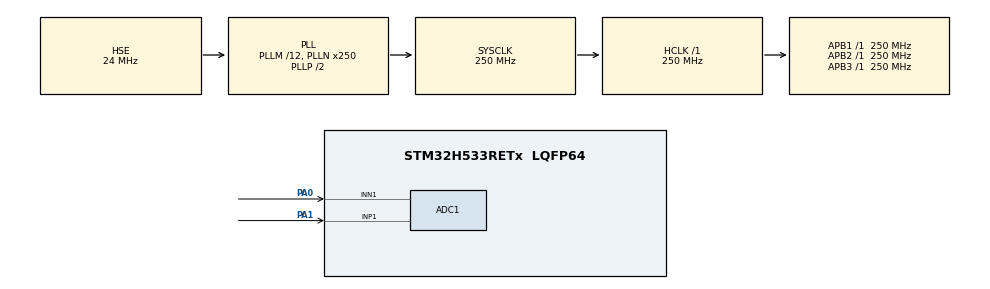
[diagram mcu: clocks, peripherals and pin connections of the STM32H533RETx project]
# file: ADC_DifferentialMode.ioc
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ADC1.Channel-0\#ChannelRegularConversion=ADC_CHANNEL_1
ADC1.ClockPrescaler=ADC_CLOCK_ASYNC_DIV1
ADC1.ContinuousConvMode=ENABLE
ADC1.MonitoredBy-0\#ChannelRegularConversion=__NULL
ADC1.NbrOfConversionFlag=1
ADC1.OffsetNumber-0\#ChannelRegularConversion=ADC_OFFSET_NONE
ADC1.Overrun=ADC_OVR_DATA_OVERWRITTEN
ADC1.Rank-0\#ChannelRegularConversion=1
ADC1.SamplingTime-0\#ChannelRegularConversion=ADC_SAMPLETIME_2CYCLES_5
ADC1.SingleDiff-0\#ChannelRegularConversion=ADC_DIFFERENTIAL_ENDED
ADC1.master=1
BOOTPATH.BootPathName=LEGACY
BOOTPATH.UserSelectedBootPath=LEGACY
CORTEX_M33_NS.userName=CORTEX_M33
Mcu.Family=STM32H5
Mcu.Name=STM32H533RETx
Mcu.Package=LQFP64
NVIC.PriorityGroup=NVIC_PRIORITYGROUP_4
PA0.Signal=ADCx_INN1
PA1.Signal=ADCx_INP1
PH0-OSC_IN(PH0).Mode=HSE-External-Oscillator
PH0-OSC_IN(PH0).Signal=RCC_OSC_IN
PH1-OSC_OUT(PH1).Mode=HSE-External-Oscillator
PH1-OSC_OUT(PH1).Signal=RCC_OSC_OUT
ProjectManager.HeapSize=0x200
ProjectManager.StackSize=0x400
ProjectManager.TargetToolchain=EWARM V9.20
RCC.ADCCLockSelection=RCC_ADCDACCLKSOURCE_HSI
RCC.ADCFreq_Value=64000000
RCC.AHBFreq_Value=250000000
RCC.APB1Freq_Value=250000000
RCC.APB1TimFreq_Value=250000000
RCC.APB2Freq_Value=250000000
RCC.APB2TimFreq_Value=250000000
RCC.APB3Freq_Value=250000000
RCC.CSI_VALUE=4000000
RCC.CortexFreq_Value=250000000
RCC.EPOD_VALUE=24000000
RCC.HCLKFreq_Value=250000000
RCC.HSE_VALUE=24000000
RCC.HSI48_VALUE=48000000
RCC.HSIDiv=RCC_HSI_DIV1
RCC.HSI_VALUE=64000000
RCC.LSE_VALUE=32768
RCC.LSIRC_VALUE=32000
RCC.PLL2FRACN=0
RCC.PLL3FRACN=0
RCC.PLLFRACN=0
RCC.PLLM=12
RCC.PLLN=250
RCC.PLLSourceVirtual=RCC_PLL1_SOURCE_HSE
RCC.SYSCLKFreq_VALUE=250000000
RCC.SYSCLKSource=RCC_SYSCLKSOURCE_PLLCLK
RCC.USBFreq_Value=48000000
RCC.VCOOutputFreq_Value=500000000
SH.ADCx_INN1.0=ADC1_INN1,IN1-Differential
SH.ADCx_INP1.0=ADC1_INP1,IN1-Differential
VP_BOOTPATH_VS_BOOTPATH.Mode=BP_Activate
VP_CORTEX_M33_NS_VS_Hclk.Mode=Hclk_Mode
VP_ICACHE_VS_ICACHE.Mode=DefaultMode
VP_MEMORYMAP_VS_MEMORYMAP.Mode=CurAppReg
VP_PWR_VS_DBSignals.Mode=DisableDeadBatterySignals
VP_PWR_VS_LPOM.Mode=PowerOptimisation
VP_PWR_VS_SECSignals.Mode=Security/Privilege
board=custom

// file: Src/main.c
/* USER CODE BEGIN Header */
/**
  ******************************************************************************
  * @file           : main.c
  * @brief          : Main program body
  ******************************************************************************
  * @attention
  *
  * Copyright (c) 2023 STMicroelectronics.
  * All rights reserved.
  *
  * This software is licensed under terms that can be found in the LICENSE file
  * in the root directory of this software component.
  * If no LICENSE file comes with this software, it is provided AS-IS.
  *
  ******************************************************************************
  */
/* USER CODE END Header */
#include "main.h"

ADC_HandleTypeDef hadc1;

/* USER CODE BEGIN PV */
/* Converted value declaration */
uint32_t                 uhADCxConvertedData;
/* Input voltage declaration */
int32_t                  uhADCxConvertedData_Voltage_mVolt;
/* USER CODE END PV */

void SystemClock_Config(void);
static void MX_GPIO_Init(void);
static void MX_ADC1_Init(void);
static void MX_ICACHE_Init(void);

int main(void)
{

  /* USER CODE BEGIN 1 */
  /* STM32H5xx HAL library initialization:
       - Systick timer is configured by default as source of time base, but user
             can eventually implement his proper time base source (a general purpose
             timer for example or other time source), keeping in mind that Time base
             duration should be kept 1ms since PPP_TIMEOUT_VALUEs are defined and
             handled in milliseconds basis.
       - Set NVIC Group Priority to 4
       - Low Level Initialization
     */
  /* USER CODE END 1 */

  /* MCU Configuration--------------------------------------------------------*/

  /* Reset of all peripherals, Initializes the Flash interface and the Systick. */
  HAL_Init();

  /* Configure the system clock */
  SystemClock_Config();

  /* Initialize all configured peripherals */
  MX_GPIO_Init();
  MX_ADC1_Init();
  MX_ICACHE_Init();

  /* Infinite loop */
  /* USER CODE BEGIN WHILE */
  while (1)
  {
    if (HAL_ADC_PollForConversion(&hadc1, 10) != HAL_OK)
    {
      Error_Handler();
    }

    /* Read the converted value */
    uhADCxConvertedData = HAL_ADC_GetValue(&hadc1);

    /* Computation of ADC conversions raw data to physical values             */
    /* using helper macro.                                                    */
    uhADCxConvertedData_Voltage_mVolt = __HAL_ADC_CALC_DIFF_DATA_TO_VOLTAGE(VDDA_APPLI, uhADCxConvertedData, ADC_RESOLUTION_12B);
    /* USER CODE END WHILE */

  }
}

void SystemClock_Config(void)
{
  RCC_OscInitTypeDef RCC_OscInitStruct = {0};
  RCC_ClkInitTypeDef RCC_ClkInitStruct = {0};

  /** Configure the main internal regulator output voltage
  */
  __HAL_PWR_VOLTAGESCALING_CONFIG(PWR_REGULATOR_VOLTAGE_SCALE0);

  while(!__HAL_PWR_GET_FLAG(PWR_FLAG_VOSRDY)) {}

  /** Initializes the RCC Oscillators according to the specified parameters
  * in the RCC_OscInitTypeDef structure.
  */
  RCC_OscInitStruct.OscillatorType = RCC_OSCILLATORTYPE_HSI|RCC_OSCILLATORTYPE_HSE;
  RCC_OscInitStruct.HSEState = RCC_HSE_ON;
  RCC_OscInitStruct.HSIState = RCC_HSI_ON;
  RCC_OscInitStruct.HSIDiv = RCC_HSI_DIV1;
  RCC_OscInitStruct.HSICalibrationValue = RCC_HSICALIBRATION_DEFAULT;
  RCC_OscInitStruct.PLL.PLLState = RCC_PLL_ON;
  RCC_OscInitStruct.PLL.PLLSource = RCC_PLL1_SOURCE_HSE;
  RCC_OscInitStruct.PLL.PLLM = 12;
  RCC_OscInitStruct.PLL.PLLN = 250;
  RCC_OscInitStruct.PLL.PLLP = 2;
  RCC_OscInitStruct.PLL.PLLQ = 2;
  RCC_OscInitStruct.PLL.PLLR = 2;
  RCC_OscInitStruct.PLL.PLLRGE = RCC_PLL1_VCIRANGE_1;
  RCC_OscInitStruct.PLL.PLLVCOSEL = RCC_PLL1_VCORANGE_WIDE;
  RCC_OscInitStruct.PLL.PLLFRACN = 0;
  if (HAL_RCC_OscConfig(&RCC_OscInitStruct) != HAL_OK)
  {
    Error_Handler();
  }

  /** Initializes the CPU, AHB and APB buses clocks
  */
  RCC_ClkInitStruct.ClockType = RCC_CLOCKTYPE_HCLK|RCC_CLOCKTYPE_SYSCLK
                              |RCC_CLOCKTYPE_PCLK1|RCC_CLOCKTYPE_PCLK2
                              |RCC_CLOCKTYPE_PCLK3;
  RCC_ClkInitStruct.SYSCLKSource = RCC_SYSCLKSOURCE_PLLCLK;
  RCC_ClkInitStruct.AHBCLKDivider = RCC_SYSCLK_DIV1;
  RCC_ClkInitStruct.APB1CLKDivider = RCC_HCLK_DIV1;
  RCC_ClkInitStruct.APB2CLKDivider = RCC_HCLK_DIV1;
  RCC_ClkInitStruct.APB3CLKDivider = RCC_HCLK_DIV1;

  if (HAL_RCC_ClockConfig(&RCC_ClkInitStruct, FLASH_LATENCY_5) != HAL_OK)
  {
    Error_Handler();
  }

  /** Configure the programming delay
  */
  __HAL_FLASH_SET_PROGRAM_DELAY(FLASH_PROGRAMMING_DELAY_2);
}

static void MX_ADC1_Init(void)
{

  ADC_ChannelConfTypeDef sConfig = {0};

  /** Common config
  */
  hadc1.Instance = ADC1;
  hadc1.Init.ClockPrescaler = ADC_CLOCK_ASYNC_DIV1;
  hadc1.Init.Resolution = ADC_RESOLUTION_12B;
  hadc1.Init.DataAlign = ADC_DATAALIGN_RIGHT;
  hadc1.Init.ScanConvMode = ADC_SCAN_DISABLE;
  hadc1.Init.EOCSelection = ADC_EOC_SINGLE_CONV;
  hadc1.Init.LowPowerAutoWait = DISABLE;
  hadc1.Init.ContinuousConvMode = ENABLE;
  hadc1.Init.NbrOfConversion = 1;
  hadc1.Init.DiscontinuousConvMode = DISABLE;
  hadc1.Init.ExternalTrigConv = ADC_SOFTWARE_START;
  hadc1.Init.ExternalTrigConvEdge = ADC_EXTERNALTRIGCONVEDGE_NONE;
  hadc1.Init.DMAContinuousRequests = DISABLE;
  hadc1.Init.SamplingMode = ADC_SAMPLING_MODE_NORMAL;
  hadc1.Init.Overrun = ADC_OVR_DATA_OVERWRITTEN;
  hadc1.Init.OversamplingMode = DISABLE;
  if (HAL_ADC_Init(&hadc1) != HAL_OK)
  {
    Error_Handler();
  }

  /** Configure Regular Channel
  */
  sConfig.Channel = ADC_CHANNEL_1;
  sConfig.Rank = ADC_REGULAR_RANK_1;
  sConfig.SamplingTime = ADC_SAMPLETIME_2CYCLES_5;
  sConfig.SingleDiff = ADC_DIFFERENTIAL_ENDED;
  sConfig.OffsetNumber = ADC_OFFSET_NONE;
  sConfig.Offset = 0;
  if (HAL_ADC_ConfigChannel(&hadc1, &sConfig) != HAL_OK)
  {
    Error_Handler();
  }
  /* USER CODE BEGIN ADC1_Init 2 */
  if (HAL_ADCEx_Calibration_Start(&hadc1, ADC_DIFFERENTIAL_ENDED) != HAL_OK)
  {
    Error_Handler();
  }

  if (HAL_ADC_Start(&hadc1) != HAL_OK)
  {
    Error_Handler();
  }
  /* USER CODE END ADC1_Init 2 */

}

static void MX_ICACHE_Init(void)
{

  /** Enable instruction cache (default 2-ways set associative cache)
  */
  if (HAL_ICACHE_Enable() != HAL_OK)
  {
    Error_Handler();
  }

}

static void MX_GPIO_Init(void)
{

  /* GPIO Ports Clock Enable */
  __HAL_RCC_GPIOH_CLK_ENABLE();
  __HAL_RCC_GPIOA_CLK_ENABLE();

}

void Error_Handler(void)
{
  __disable_irq();
  while (1)
  {
  }
}
